# STM8AF5269 register map
Vendor: STMicroelectronics; Series: STM8S/STM8AF, medium density; File version: 1.0
CPU: other r1p0, big endian, no MPU, no FPU, 4 interrupt priority bits
Registers are 8-bit, read-write, reset 0x0 unless marked. A register's access mark holds for its fields unless they carry their own. Offsets are from the block's base; [hi:lo] are bit positions; {n}, {i} and the like mark numbered series.

## ITC
Base 0x000050A0
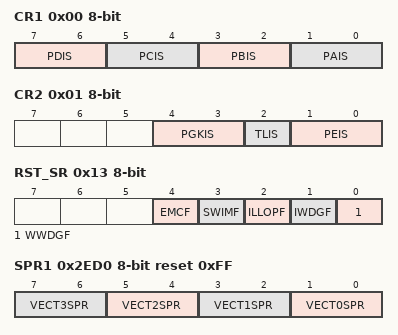
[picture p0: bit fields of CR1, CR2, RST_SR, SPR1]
0x00 CR1 — External interrupt control register 1
  [7:6] PDIS, [5:4] PCIS, [3:2] PBIS, [1:0] PAIS
0x01 CR2 — External interrupt control register 2
  [4:3] PGKIS, [2] TLIS, [1:0] PEIS
0x13 RST_SR — Reset status register
  [4] EMCF, [3] SWIMF, [2] ILLOPF, [1] IWDGF, [0] WWDGF
0x2ED0 SPR1 reset 0xFF — Interrupt software priority register 1
  [2n+1:2n] VECT{n}SPR (n=0..3)
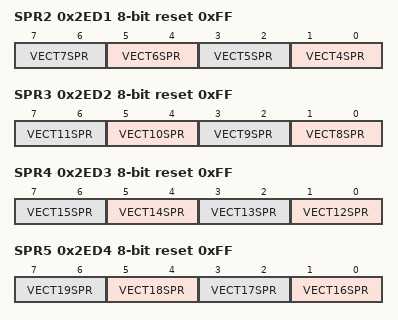
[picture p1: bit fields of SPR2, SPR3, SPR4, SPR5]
0x2ED1 SPR2 reset 0xFF — Interrupt software priority register 2
  [2n-7:2n-8] VECT{n}SPR (n=4..7)
0x2ED2 SPR3 reset 0xFF — Interrupt software priority register 3
  [2n-15:2n-16] VECT{n}SPR (n=8..11)
0x2ED3 SPR4 reset 0xFF — Interrupt software priority register 4
  [2n-23:2n-24] VECT{n}SPR (n=12..15)
0x2ED4 SPR5 reset 0xFF — Interrupt software priority register 5
  [2n-31:2n-32] VECT{n}SPR (n=16..19)
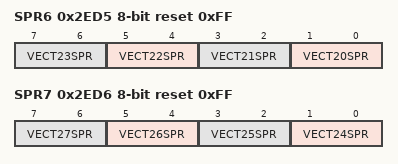
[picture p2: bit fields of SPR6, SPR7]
0x2ED5 SPR6 reset 0xFF — Interrupt software priority register 6
  [2n-39:2n-40] VECT{n}SPR (n=20..23)
0x2ED6 SPR7 reset 0xFF — Interrupt software priority register 7
  [2n-47:2n-48] VECT{n}SPR (n=24..27)

## IWDG
Base 0x000050E0
0x00 KR — IWDG key register
0x01 PR — IWDG prescaler register
  [2:0] PR
0x02 RLR reset 0xFF — IWDG reload register
  [7:0] RL

## LINUART
Base 0x00005240
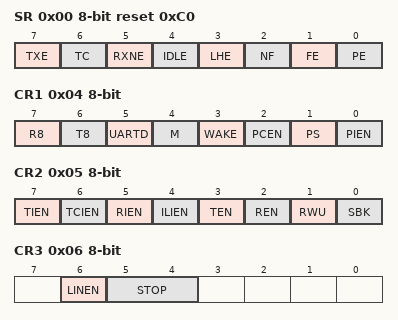
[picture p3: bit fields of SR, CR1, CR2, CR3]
0x00 SR reset 0xC0 — LINUART status register
  [7] TXE, [6] TC, [5] RXNE, [4] IDLE, [3] LHE, [2] NF, [1] FE, [0] PE
0x01 DR — LINUART data register
0x02 BRR1 — LINUART baud rate register 1
  [7:0] LDIV
0x03 BRR2 — LINUART baud rate register 2
  [7:0] LDIV
0x04 CR1 — LINUART control register 1
  [7] R8, [6] T8, [5] UARTD, [4] M, [3] WAKE, [2] PCEN, [1] PS, [0] PIEN
0x05 CR2 — LINUART control register 2
  [7] TIEN, [6] TCIEN, [5] RIEN, [4] ILIEN, [3] TEN, [2] REN, [1] RWU, [0] SBK
0x06 CR3 — LINUART control register 3
  [6] LINEN, [5:4] STOP
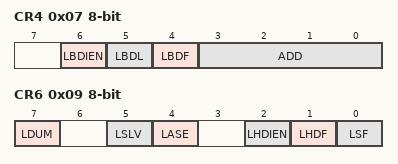
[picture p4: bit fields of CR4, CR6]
0x07 CR4 — LINUART control register 4
  [6] LBDIEN, [5] LBDL, [4] LBDF, [3:0] ADD
0x09 CR6 — LINUART control register 6
  [7] LDUM, [5] LSLV, [4] LASE, [2] LHDIEN, [1] LHDF, [0] LSF

## OPT
Base 0x00004800
0x00 OPT0 — Read-out protection (ROP)
0x01 OPT1 — User boot code (UBC)
0x02 NOPT1 reset 0xFF — User boot code (UBC) (complementary byte)
0x03 OPT2 — Alternate function remapping (AFR)
0x04 NOPT2 reset 0xFF — Alternate function remapping (AFR) (complementary byte)
0x05 OPT3 — Watchdog option
0x06 NOPT3 reset 0xFF — Watchdog option (complementary byte)
0x07 OPT4 — Clock option
0x08 NOPT4 reset 0xFF — Clock option (complementary byte)
0x09 OPT5 — HSE clock startup
0x0A NOPT5 reset 0xFF — HSE clock startup (complementary byte)
0x0B OPT6 — TMU
0x0C NOPT6 reset 0xFF — TMU (complementary byte)
0x0D OPT7 — Flash wait states
0x0E NOPT7 reset 0xFF — Flash wait states (complementary byte)
{0x8+i} OPT{i} (i=8..15) — TMU_KEY {i-7}
0x18 OPT16 reset 0xC7 — TMU_MAXATT
0x7E OPT17 — Bootloader
0x7F NOPT17 reset 0xFF — Bootloader (complementary byte)

## PORTA
Base 0x00005000
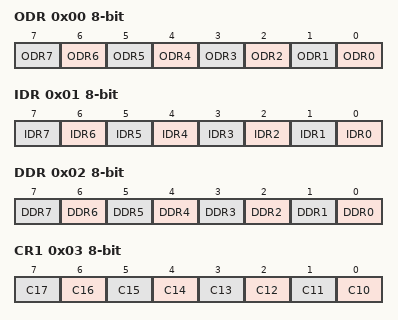
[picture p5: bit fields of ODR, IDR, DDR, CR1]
0x00 ODR — Port A data output latch register
  [n] ODR{n} (n=0..7)
0x01 IDR — Port A input pin value register
  [n] IDR{n} (n=0..7)
0x02 DDR — Port A data direction register
  [n] DDR{n} (n=0..7)
0x03 CR1 — Port A control register 1
  [n-10] C{n} (n=10..17)
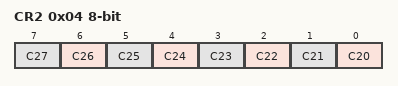
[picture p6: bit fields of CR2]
0x04 CR2 — Port A control register 2
  [n-20] C{n} (n=20..27)

## PORTB
Base 0x00005005
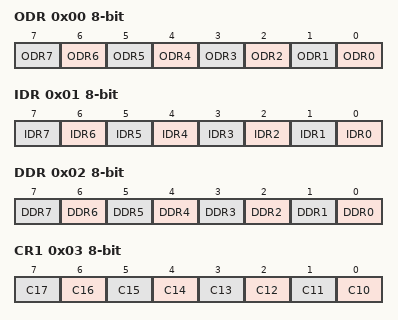
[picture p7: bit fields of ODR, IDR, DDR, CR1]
0x00 ODR — Port B data output latch register
  [n] ODR{n} (n=0..7)
0x01 IDR — Port B input pin value register
  [n] IDR{n} (n=0..7)
0x02 DDR — Port B data direction register
  [n] DDR{n} (n=0..7)
0x03 CR1 — Port B control register 1
  [n-10] C{n} (n=10..17)
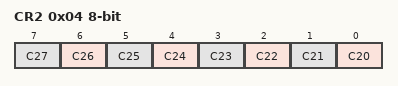
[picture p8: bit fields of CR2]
0x04 CR2 — Port B control register 2
  [n-20] C{n} (n=20..27)

## PORTC
Base 0x0000500A
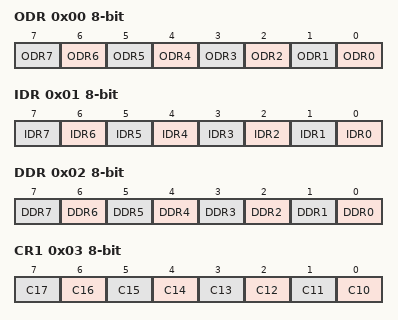
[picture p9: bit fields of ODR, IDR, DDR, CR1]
0x00 ODR — Port C data output latch register
  [n] ODR{n} (n=0..7)
0x01 IDR — Port C input pin value register
  [n] IDR{n} (n=0..7)
0x02 DDR — Port C data direction register
  [n] DDR{n} (n=0..7)
0x03 CR1 — Port C control register 1
  [n-10] C{n} (n=10..17)
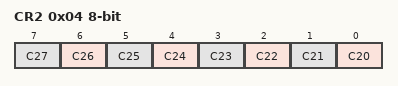
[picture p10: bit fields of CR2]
0x04 CR2 — Port C control register 2
  [n-20] C{n} (n=20..27)
